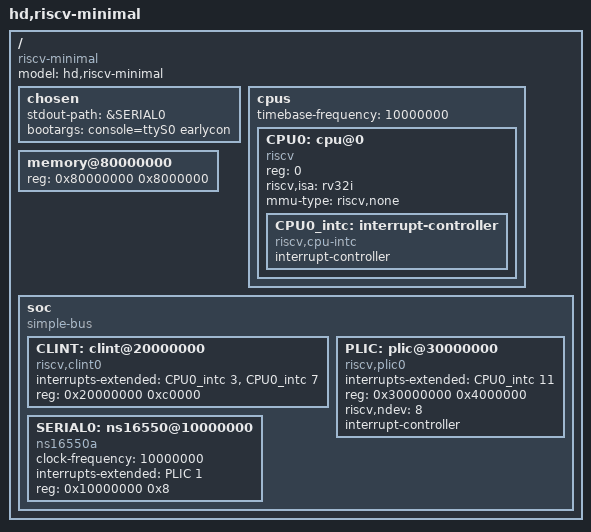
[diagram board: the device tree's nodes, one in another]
/dts-v1/;

/ {
    #address-cells = <1>;
    #size-cells = <1>;

    compatible = "riscv-minimal";
    model = "hd,riscv-minimal";

    chosen {
        stdout-path = &SERIAL0;
        bootargs = "console=ttyS0 earlycon";
    };

    cpus {
        #address-cells = <1>;
        #size-cells = <0>;
        timebase-frequency = <10000000>; // mtime freq

        CPU0: cpu@0 {
            device_type = "cpu";
            reg = <0>;
            status = "okay";
            compatible = "riscv";
            riscv,isa = "rv32i";
            mmu-type = "riscv,none";

            CPU0_intc: interrupt-controller {
                #interrupt-cells = <1>;
                interrupt-controller;
                compatible = "riscv,cpu-intc";
            };
        };
    };

    memory@80000000 {
        device_type = "memory";
        reg = <0x80000000 0x8000000>; // 128 mb
    };

    soc {
        compatible = "simple-bus";
        #address-cells = <1>;
        #size-cells = <1>;
        ranges;

        CLINT: clint@20000000 {
            compatible = "riscv,clint0";
            interrupts-extended = <&CPU0_intc 3 &CPU0_intc 7>; // MSIP, MTIP
            reg = <0x20000000 0xc0000>;
        };

        PLIC: plic@30000000 {
            compatible = "riscv,plic0";
            interrupts-extended = <&CPU0_intc 11>; // MEIP
            reg = <0x30000000 0x4000000>;
            riscv,ndev = <8>;
            #interrupt-cells = <1>;
            interrupt-controller;
        };

        SERIAL0: ns16550@10000000 {
            compatible = "ns16550a";
            clock-frequency = <10000000>; // used for baud divisor calculation
            interrupts-extended = <&PLIC 1>;
            reg = <0x10000000 0x8>;
        };
    };
};
